# AT32UC3L064 device description
Architecture: AVR32_UC3; Family: AVR UC3
Registers are 32-bit, read-write, reset 0x0 unless marked. A register's access mark holds for its fields unless they carry their own. Offsets are from the block's base; [hi:lo] are bit positions; {n}, {i} and the like mark numbered series; 'fields as' and 'values as' point back to an identical list.

## SCIF — System Control Interface
Instances: SCIF 0xffff1800
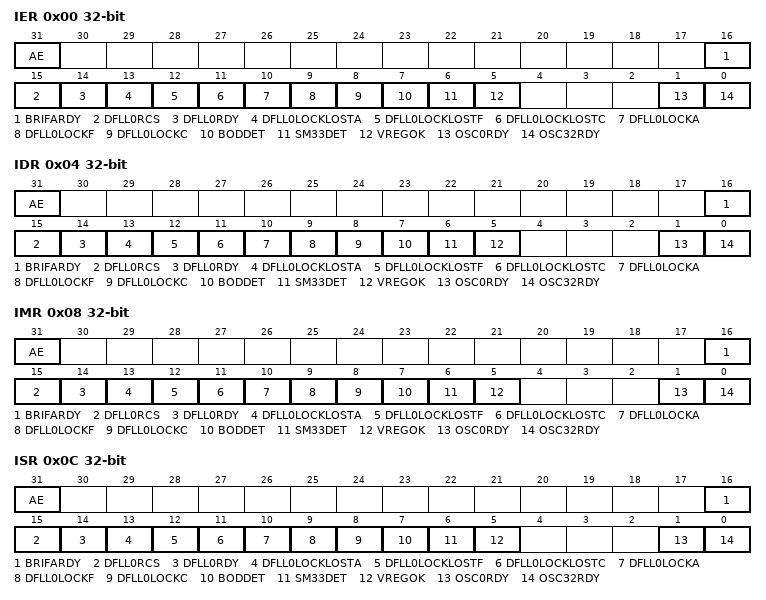
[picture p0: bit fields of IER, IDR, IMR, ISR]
0x00 IER wo
  [31] AE, [16] BRIFARDY, [15] DFLL0RCS, [14] DFLL0RDY, [13] DFLL0LOCKLOSTA, [12] DFLL0LOCKLOSTF, [11] DFLL0LOCKLOSTC, [10] DFLL0LOCKA, [9] DFLL0LOCKF, [8] DFLL0LOCKC, [7] BODDET, [6] SM33DET, [5] VREGOK, [1] OSC0RDY, [0] OSC32RDY
0x04 IDR wo
  fields as IER
0x08 IMR ro
  fields as IER
0x0C ISR ro
  fields as IER
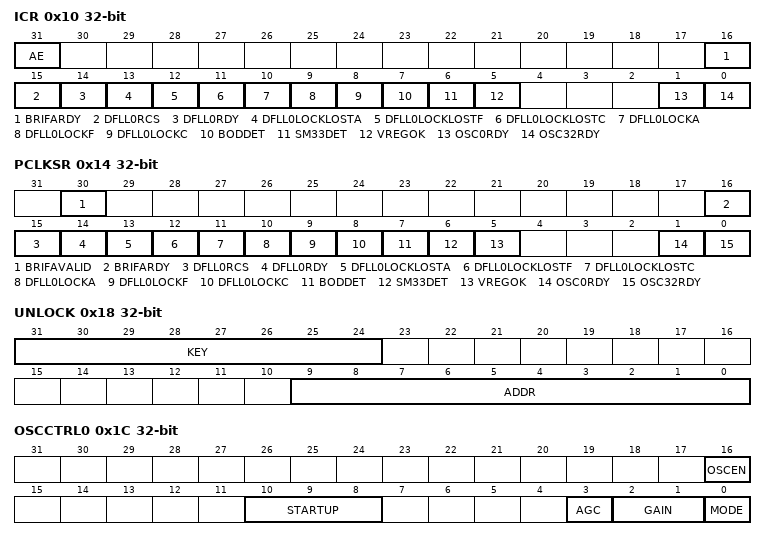
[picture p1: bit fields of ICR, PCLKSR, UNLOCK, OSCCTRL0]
0x10 ICR wo
  fields as IER
0x14 PCLKSR ro
  [30] BRIFAVALID, [16] BRIFARDY, [15] DFLL0RCS, [14] DFLL0RDY, [13] DFLL0LOCKLOSTA, [12] DFLL0LOCKLOSTF, [11] DFLL0LOCKLOSTC, [10] DFLL0LOCKA, [9] DFLL0LOCKF, [8] DFLL0LOCKC, [7] BODDET, [6] SM33DET, [5] VREGOK, [1] OSC0RDY, [0] OSC32RDY
0x18 UNLOCK wo
  [31:24] KEY, [9:0] ADDR
0x1C OSCCTRL0
  [16] OSCEN, [10:8] STARTUP, [3] AGC, [2:1] GAIN, [0] MODE
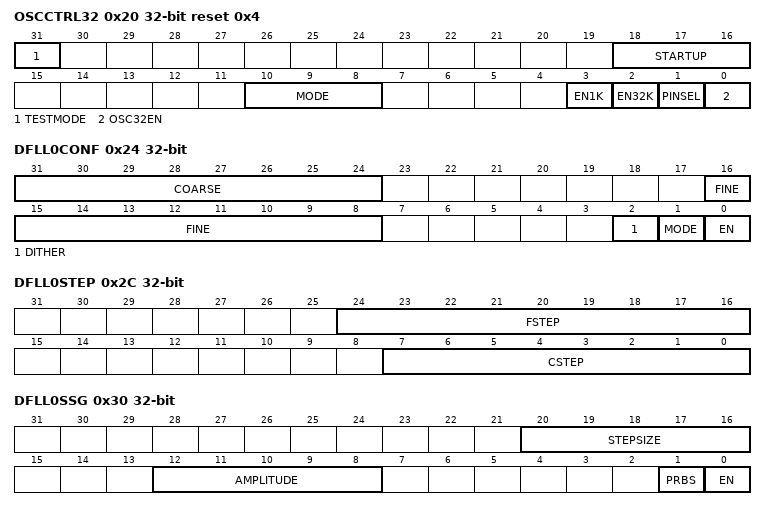
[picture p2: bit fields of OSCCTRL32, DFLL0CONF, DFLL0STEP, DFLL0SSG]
0x20 OSCCTRL32 reset 0x4
  [31] TESTMODE — Enable 32KHz oscillator test mode
  [18:16] STARTUP — 32KHz Oscillator Startup Time
  [10:8] MODE — 32KHz Oscillator Mode
  [3] EN1K — Enable 1KHz output
  [2] EN32K — Enable 32KHz output
  [1] PINSEL — Select pins used for 32KHz crystal oscillator
  [0] OSC32EN — Enable the 32KHz oscillator
0x24 DFLL0CONF
  [31:24] COARSE, [16:8] FINE, [2] DITHER, [1] MODE, [0] EN
0x28 DFLL0FMUL
  [31:0] FMUL
0x2C DFLL0STEP
  [24:16] FSTEP, [7:0] CSTEP
0x30 DFLL0SSG
  [20:16] STEPSIZE, [12:8] AMPLITUDE, [1] PRBS, [0] EN
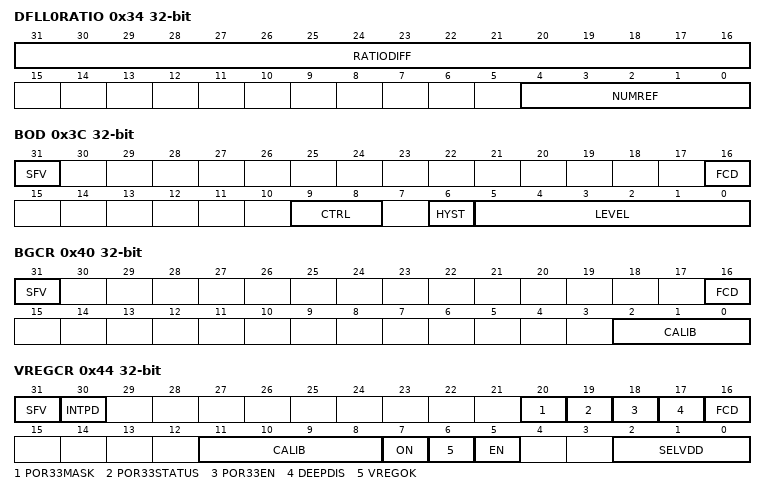
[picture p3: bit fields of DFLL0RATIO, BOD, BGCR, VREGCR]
0x34 DFLL0RATIO ro
  [31:16] RATIODIFF, [4:0] NUMREF
0x38 DFLL0SYNC wo
  [0] SYNC
0x3C BOD reset not defined
  [31] SFV — Stor final value
  [16] FCD — BOD Fuse calibration done
  [9:8] CTRL — BOD Control
  [6] HYST — BOD Hysteresis
  [5:0] LEVEL — BOD Level
0x40 BGCR reset not defined
  [31] SFV — Stor final value
  [16] FCD — Flash Calibration Done
  [2:0] CALIB — Calibration value
0x44 VREGCR reset not defined
  [31] SFV — Store final value
  [30] INTPD — Internal Pulldown
  [20] POR33MASK — POR33 output mask
  [19] POR33STATUS — POR33 status (active/inactive)
  [18] POR33EN — Enable POR33
  [17] DEEPDIS — Disable regulator deep mode
  [16] FCD — Flash calibration done
  [11:8] CALIB — Voltage regulator calibration
  [7] ON — Voltage Regulator Status
  [6] VREGOK — Voltage is correct
  [5] EN
  [2:0] SELVDD — Select VDD
    0=VDD1V35; 1=VDD1V45; 2=VDD1V55; 3=VDD1V65; 4=VDD1V75; 5=VDD1V80
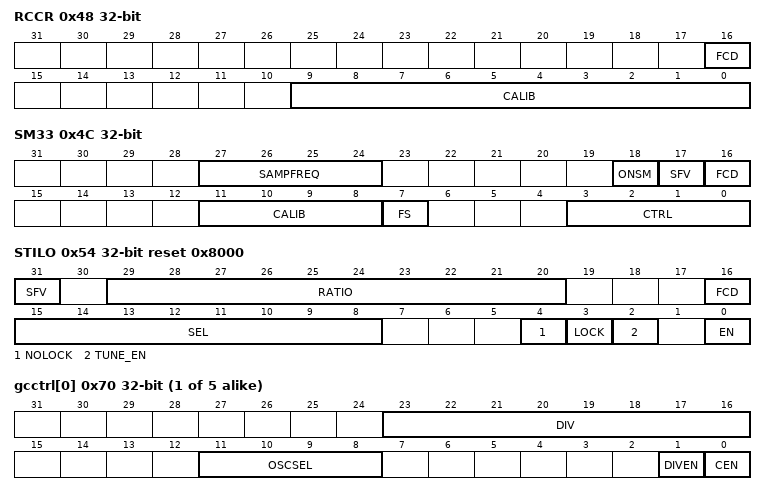
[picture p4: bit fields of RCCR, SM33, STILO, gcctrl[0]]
0x48 RCCR reset not defined
  [16] FCD — Flash Calibration Done
  [9:0] CALIB — Calibration Value
0x4C SM33 reset not defined
  [27:24] SAMPFREQ — Sampling Frequency
  [18] ONSM — Supply monitor on
  [17] SFV — Store final value
  [16] FCD — Fuse Calibration Done
  [11:8] CALIB — Calibration register
  [7] FS — Force Sampling mode
  [3:0] CTRL — Supply monitor Control
0x50 TSENS
  [0] EN — Enable
0x54 STILO reset 0x8000
  [31] SFV — Store final value
  [29:20] RATIO — Target clock ratio
  [16] FCD — Fuse calibration done
  [15:8] SEL — Margin selection
  [4] NOLOCK — No lock on frequency
  [3] LOCK — Lock on frequency
  [2] TUNE_EN — Tuner enable
  [0] EN — CRIPOSC enable bit
0x58 RC120MCR
  [0] EN — Enable bit
{0x5C+4i} br[{i}] (i=0..3) access not given
0x6C RC32KCR
  [0] EN — Enable bit
{0x70+4i} gcctrl[{i}] (i=0..4) access not given
  [23:16] DIV — Division Factor
  [11:8] OSCSEL — Clock Select
  [1] DIVEN — Divide enable
  [0] CEN — Clock Enable
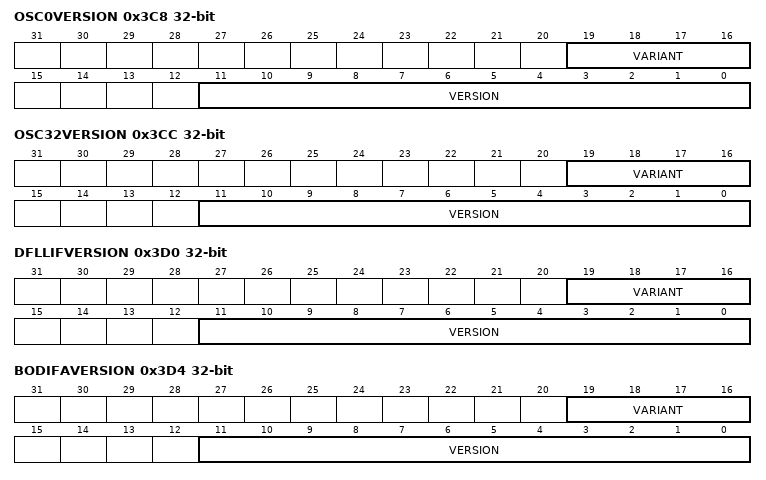
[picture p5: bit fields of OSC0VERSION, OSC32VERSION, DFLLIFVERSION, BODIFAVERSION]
0x3C8 OSC0VERSION ro reset not defined
  [19:16] VARIANT, [11:0] VERSION
0x3CC OSC32VERSION ro reset not defined
  [19:16] VARIANT, [11:0] VERSION
0x3D0 DFLLIFVERSION ro reset not defined
  [19:16] VARIANT, [11:0] VERSION
0x3D4 BODIFAVERSION ro reset not defined
  [19:16] VARIANT, [11:0] VERSION
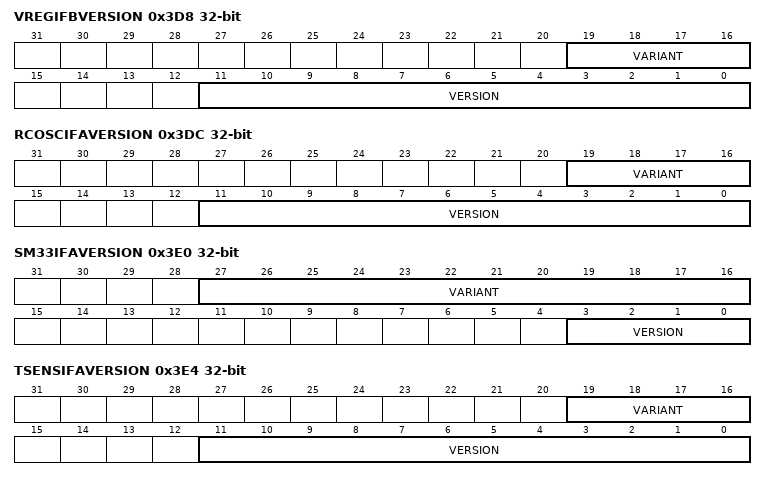
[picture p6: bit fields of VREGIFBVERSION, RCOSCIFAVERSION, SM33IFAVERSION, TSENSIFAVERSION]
0x3D8 VREGIFBVERSION ro reset not defined
  [19:16] VARIANT, [11:0] VERSION
0x3DC RCOSCIFAVERSION ro reset not defined
  [19:16] VARIANT, [11:0] VERSION
0x3E0 SM33IFAVERSION ro reset not defined
  [27:16] VARIANT, [3:0] VERSION
0x3E4 TSENSIFAVERSION ro reset not defined
  [19:16] VARIANT, [11:0] VERSION
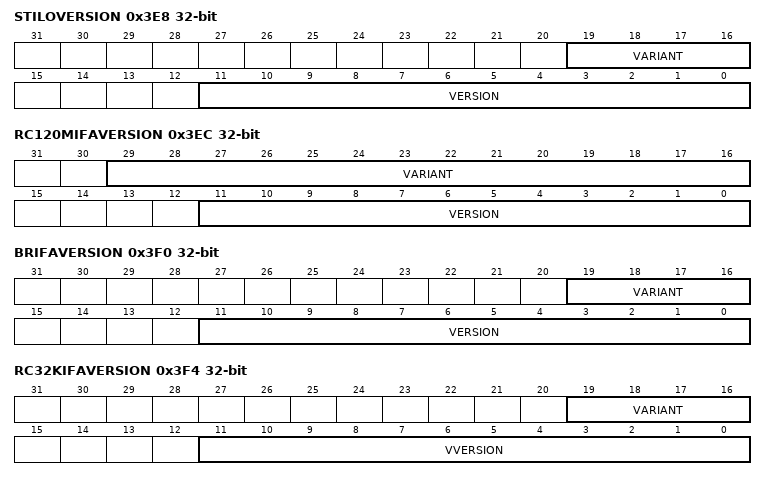
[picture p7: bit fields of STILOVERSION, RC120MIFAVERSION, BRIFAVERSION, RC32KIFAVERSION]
0x3E8 STILOVERSION ro reset not defined
  [19:16] VARIANT, [11:0] VERSION
0x3EC RC120MIFAVERSION ro reset not defined
  [29:16] VARIANT, [11:0] VERSION
0x3F0 BRIFAVERSION ro reset not defined
  [19:16] VARIANT, [11:0] VERSION
0x3F4 RC32KIFAVERSION ro reset not defined
  [19:16] VARIANT, [11:0] VVERSION
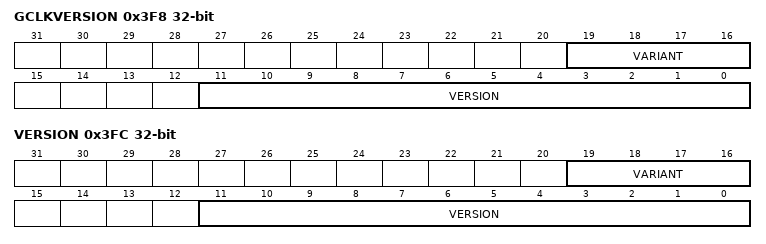
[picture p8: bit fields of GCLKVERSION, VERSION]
0x3F8 GCLKVERSION ro reset not defined
  [19:16] VARIANT, [11:0] VERSION
0x3FC VERSION ro reset not defined
  [19:16] VARIANT, [11:0] VERSION
